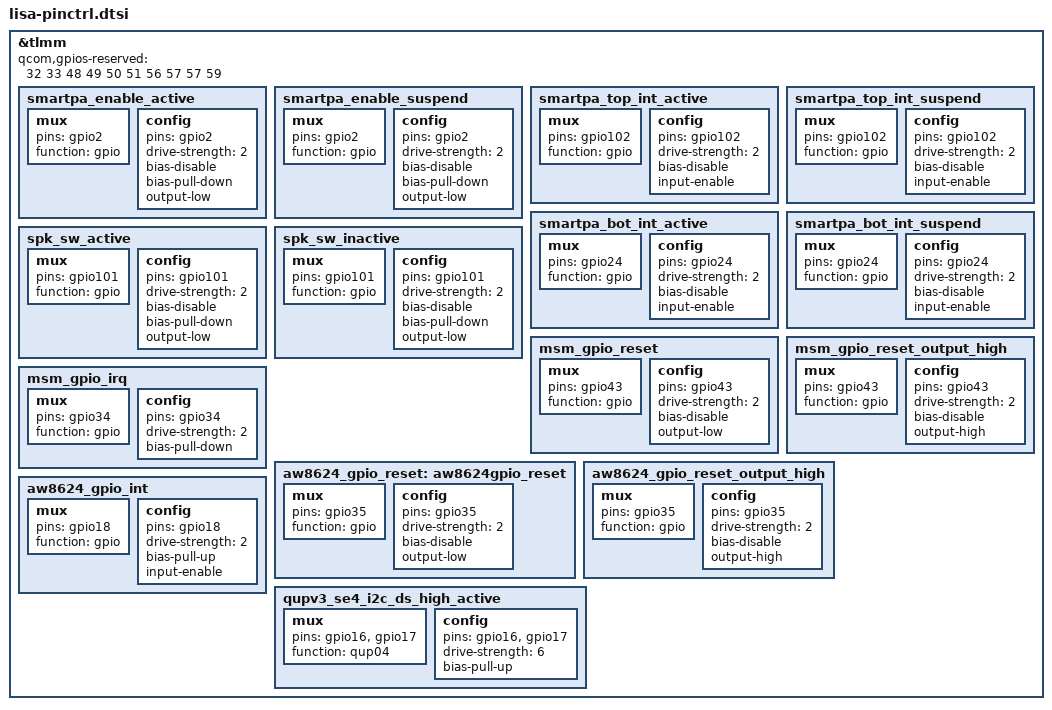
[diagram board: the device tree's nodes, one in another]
&tlmm {
	qcom,gpios-reserved = <32 33 48 49 50 51 56 57 57 59>;

	/* active state */
	smartpa_enable_active: smartpa_enable_active {
		/* GPIO 2 rst pin */
		mux {
			pins = "gpio2";
			function = "gpio";
		};

		config {
			pins = "gpio2";
			drive-strength = <2>;
			bias-disable;
			bias-pull-down;
			output-low;
		};
	};

	/* sleep state */
	smartpa_enable_suspend: smartpa_enable_suspend {
		mux {
			/* GPIO 2 rst pin */
			pins = "gpio2";
			function = "gpio";
		};

		config {
			pins = "gpio2";
			drive-strength = <2>;
			bias-disable;
			bias-pull-down;
			output-low;
		};
	};

	/* active state */
	smartpa_top_int_active: smartpa_top_int_active {
		/* GPIO 102 Interrupt */
		mux {
			pins = "gpio102";
			function = "gpio";
		};

		config {
			pins = "gpio102";
			drive-strength = <2>; /* 2 MA */
			bias-disable;
			input-enable;
		};
	};

	/* sleep state */
	smartpa_top_int_suspend: smartpa_top_int_suspend {
		/* GPIO 102 Interrupt */
		mux {
			pins = "gpio102";
			function = "gpio";
		};

		config {
			pins = "gpio102";
			drive-strength = <2>; /* 2 MA */
			bias-disable;
			input-enable;
		};
	};

	/* active state */
	smartpa_bot_int_active: smartpa_bot_int_active {
		/* GPIO 24 Interrupt */
		mux {
			pins = "gpio24";
			function = "gpio";
		};

		config {
			pins = "gpio24";
			drive-strength = <2>; /* 2 MA */
			bias-disable;
			input-enable;
		};
	};

	/* sleep state */
	smartpa_bot_int_suspend: smartpa_bot_int_suspend {
		/* GPIO 24 Interrupt */
		mux {
			pins = "gpio24";
			function = "gpio";
		};

		config {
			pins = "gpio24";
			drive-strength = <2>; /* 2 MA */
			bias-disable;
			input-enable;
		};
	};

	/* speaker switch */
	spk_sw_active: spk_sw_active {
		mux {
			pins = "gpio101";
			function = "gpio";
		};

		config {
			pins = "gpio101";
			drive-strength = <2>;
			bias-disable;
			bias-pull-down;
			output-low;
		};
	};

	spk_sw_inactive: spk_sw_inactive {
		mux {
			pins = "gpio101";
			function = "gpio";
		};

		config {
			pins = "gpio101";
			drive-strength = <2>;
			bias-disable;
			bias-pull-down;
			output-low;
		};
	};

	/* FP_RESET_N */
	msm_gpio_reset: msm_gpio_reset {
		mux {
			pins = "gpio43";
			function = "gpio";
		};
		config {
			pins = "gpio43";
			drive-strength = <2>;
			bias-disable;
			output-low;
		};
	};

	/* FP_RESET_N, state device active*/
	msm_gpio_reset_output_high: msm_gpio_reset_output_high {
		mux {
			pins = "gpio43";
			function = "gpio";
		};
		config {
			pins = "gpio43";
			drive-strength = <2>;
			bias-disable;
			output-high;
		};
	};

	/* FP_INT_N */
	msm_gpio_irq: msm_gpio_irq {
		mux {
			pins = "gpio34";
			function = "gpio";
		};
		config {
			pins = "gpio34";
			drive-strength = <2>;
			bias-pull-down;
		};
	};

	/* AW8624_RESET_N */
	aw8624_gpio_reset: aw8624gpio_reset {
		mux {
			pins = "gpio35";
			function = "gpio";
		};

		config {
			pins = "gpio35";
			drive-strength = <2>;
			bias-disable;
			output-low;
		};
	};

	/* AW8624_RESET_N, state device active*/
	aw8624_gpio_reset_output_high: aw8624_gpio_reset_output_high {
		mux {
			pins = "gpio35";
			function = "gpio";
		};

		config {
			pins = "gpio35";
			drive-strength = <2>;
			bias-disable;
			output-high;
		};
	};

	/* AW8624_INTERRUPT_N */
	aw8624_gpio_int: aw8624_gpio_int {
		mux {
			pins = "gpio18";
			function = "gpio";
		};

		config {
			pins = "gpio18";
			drive-strength = <2>;
			bias-pull-up;
			input-enable;
		};
	};

	qupv3_se4_i2c_ds_high_active: qupv3_se4_i2c_ds_high_active {
		mux {
			pins = "gpio16", "gpio17";
			function = "qup04";
		};

		config {
			pins = "gpio16", "gpio17";
			drive-strength = <6>;//modify to for aw8624
			bias-pull-up;
		};
	};
};
